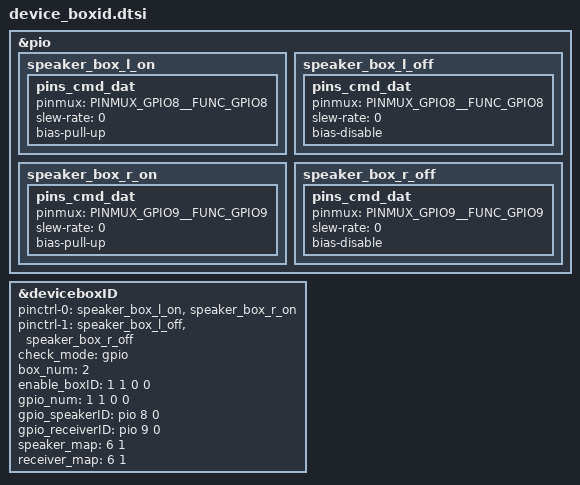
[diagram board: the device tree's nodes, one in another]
/* Box ID END */
&pio {
	speaker_box_l_on: speaker_box_l_on {
		pins_cmd_dat {
			pinmux = <PINMUX_GPIO8__FUNC_GPIO8>;
			slew-rate = <0>;
			bias-pull-up;
		};
	};
	speaker_box_l_off: speaker_box_l_off {
		pins_cmd_dat {
			pinmux = <PINMUX_GPIO8__FUNC_GPIO8>;
			slew-rate = <0>;
			bias-disable;
		};
	};
	speaker_box_r_on: speaker_box_r_on {
		pins_cmd_dat {
			pinmux = <PINMUX_GPIO9__FUNC_GPIO9>;
			slew-rate = <0>;
			bias-pull-up;
		};
	};
	speaker_box_r_off: speaker_box_r_off {
	pins_cmd_dat {
			pinmux = <PINMUX_GPIO9__FUNC_GPIO9>;
			slew-rate = <0>;
			bias-disable;
		};
	};
};

&deviceboxID {
	pinctrl-names = "default",
					"idle";
	pinctrl-0 = <&speaker_box_l_on &speaker_box_r_on>;
	pinctrl-1 = <&speaker_box_l_off &speaker_box_r_off>;
	check_mode = "gpio";
	box_num = <2>;
	enable_boxID = <1 1 0 0>;
	gpio_num = <1 1 0 0>;
	gpio_speakerID = <&pio 8 0>;
	gpio_receiverID = <&pio 9 0>;
	speaker_map = <6 1>;
	receiver_map = <6 1>;
	status = "ok";
};
/* Box ID END */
